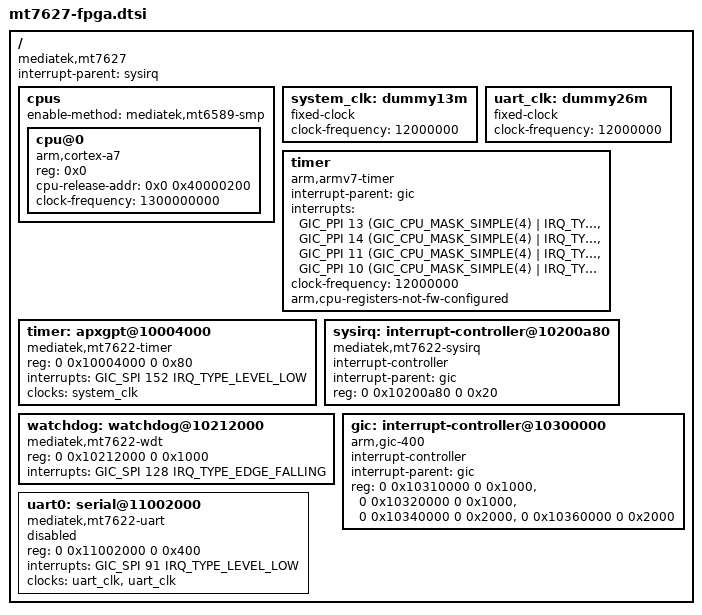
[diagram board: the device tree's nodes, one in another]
/*
 * Copyright (c) 2017 MediaTek Inc.
 * Author: Dehui.Sun <dehui.sun@mediatek.com>
 *
 * This program is free software; you can redistribute it and/or modify
 * it under the terms of the GNU General Public License version 2 as
 * published by the Free Software Foundation.
 *
 * This program is distributed in the hope that it will be useful,
 * but WITHOUT ANY WARRANTY; without even the implied warranty of
 * MERCHANTABILITY or FITNESS FOR A PARTICULAR PURPOSE.  See the
 * GNU General Public License for more details.
 */

#include <dt-bindings/interrupt-controller/irq.h>
#include <dt-bindings/interrupt-controller/arm-gic.h>
#include "skeleton64.dtsi"

/ {
	compatible = "mediatek,mt7627";
	interrupt-parent = <&sysirq>;
	#address-cells = <2>;
	#size-cells = <2>;

	cpus {
		#address-cells = <1>;
		#size-cells = <0>;
		enable-method = "mediatek,mt6589-smp";

		cpu@0 {
			device_type = "cpu";
			compatible = "arm,cortex-a7";
			reg = <0x0>;
			cpu-release-addr = <0x0 0x40000200>;
			clock-frequency = <1300000000>;
		};

	};

	system_clk: dummy13m {
		compatible = "fixed-clock";
		clock-frequency = <12000000>;
		#clock-cells = <0>;
	};

	uart_clk: dummy26m {
		compatible = "fixed-clock";
		clock-frequency = <12000000>;
		#clock-cells = <0>;
	};

	timer {
		compatible = "arm,armv7-timer";
		interrupt-parent = <&gic>;
		interrupts = <GIC_PPI 13 (GIC_CPU_MASK_SIMPLE(4) | IRQ_TYPE_LEVEL_HIGH)>,
			     <GIC_PPI 14 (GIC_CPU_MASK_SIMPLE(4) | IRQ_TYPE_LEVEL_HIGH)>,
			     <GIC_PPI 11 (GIC_CPU_MASK_SIMPLE(4) | IRQ_TYPE_LEVEL_HIGH)>,
			     <GIC_PPI 10 (GIC_CPU_MASK_SIMPLE(4) | IRQ_TYPE_LEVEL_HIGH)>;
		clock-frequency = <12000000>;
		arm,cpu-registers-not-fw-configured;
	};

	timer: apxgpt@10004000 {
		compatible = "mediatek,mt7622-timer",
			     "mediatek,mt6577-timer";
		reg = <0 0x10004000 0 0x80>;
		interrupts = <GIC_SPI 152 IRQ_TYPE_LEVEL_LOW>;
		clocks = <&system_clk>;
		clock-names = "clk13m";
	};

	sysirq: interrupt-controller@10200a80 {
		compatible = "mediatek,mt7622-sysirq",
			     "mediatek,mt6577-sysirq";
		interrupt-controller;
		#interrupt-cells = <3>;
		interrupt-parent = <&gic>;
		reg = <0 0x10200a80 0 0x20>;
	};

	watchdog: watchdog@10212000 {
		compatible = "mediatek,mt7622-wdt",
			     "mediatek,mt6589-wdt";
		reg = <0 0x10212000 0 0x1000>;
		interrupts = <GIC_SPI 128 IRQ_TYPE_EDGE_FALLING>;
		#reset-cells = <1>;
	};

	gic: interrupt-controller@10300000 {
		compatible = "arm,gic-400";
		interrupt-controller;
		#interrupt-cells = <3>;
		interrupt-parent = <&gic>;
		reg = <0 0x10310000 0 0x1000>,
		      <0 0x10320000 0 0x1000>,
		      <0 0x10340000 0 0x2000>,
		      <0 0x10360000 0 0x2000>;
	};

	uart0: serial@11002000 {
		compatible = "mediatek,mt7622-uart",
			     "mediatek,mt6577-uart";
		reg = <0 0x11002000 0 0x400>;
		interrupts = <GIC_SPI 91 IRQ_TYPE_LEVEL_LOW>;
		clocks = <&uart_clk>, <&uart_clk>;
		clock-names = "baud", "bus";
		status = "disabled";
	};
};

